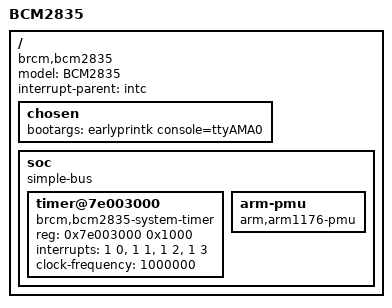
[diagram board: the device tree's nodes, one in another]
#include <dt-bindings/pinctrl/bcm2835.h>
#include "skeleton.dtsi"
#include "bcm283x-common.dtsi"

/ {
	compatible = "brcm,bcm2835";
	model = "BCM2835";
	interrupt-parent = <&intc>;

	chosen {
		bootargs = "earlyprintk console=ttyAMA0";
	};

	soc {
		compatible = "simple-bus";
		#address-cells = <1>;
		#size-cells = <1>;
		ranges = <0x7e000000 0x20000000 0x02000000>;

		timer@7e003000 {
			compatible = "brcm,bcm2835-system-timer";
			reg = <0x7e003000 0x1000>;
			interrupts = <1 0>, <1 1>, <1 2>, <1 3>;
			clock-frequency = <1000000>;
		};

		arm-pmu {
			compatible = "arm,arm1176-pmu";
		};
	};
};
